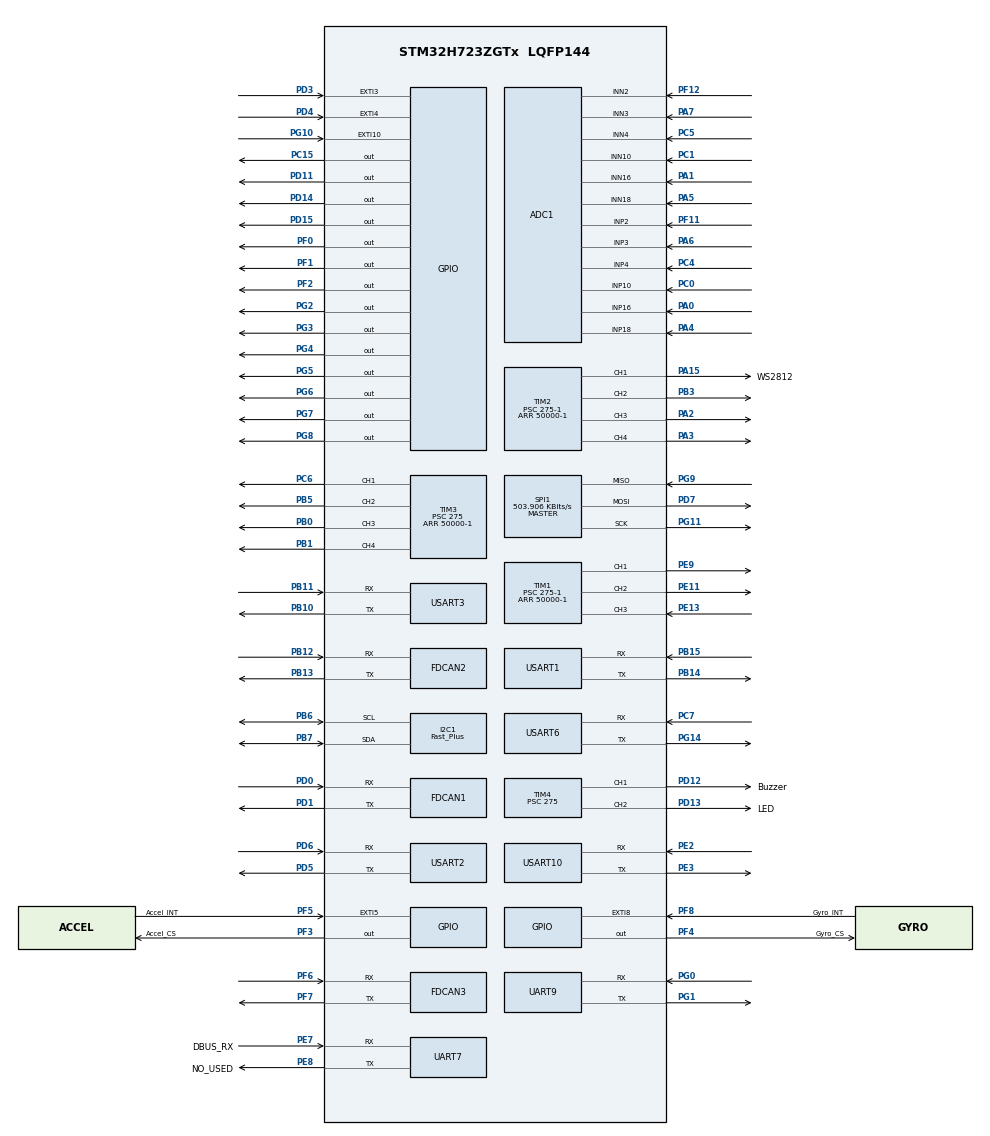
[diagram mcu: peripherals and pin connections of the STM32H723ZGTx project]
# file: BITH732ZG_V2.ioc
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ADC1.Channel-0\#ChannelRegularConversion=ADC_CHANNEL_16
ADC1.NbrOfConversionFlag=1
ADC1.OffsetNumber-0\#ChannelRegularConversion=ADC_OFFSET_NONE
ADC1.OffsetSignedSaturation-0\#ChannelRegularConversion=DISABLE
ADC1.Rank-0\#ChannelRegularConversion=1
ADC1.SamplingTime-0\#ChannelRegularConversion=ADC_SAMPLETIME_1CYCLE_5
ADC1.SingleDiff-0\#ChannelRegularConversion=ADC_DIFFERENTIAL_ENDED
ADC1.master=1
CORTEX_M7.CPU_DCache=Enabled
CORTEX_M7.CPU_ICache=Enabled
CORTEX_M7.MPU_Control=__NULL
CORTEX_M7.default_mode_Activation=1
Dma.Request0=UART7_RX
Dma.Request1=UART9_RX
Dma.Request10=USART10_TX
Dma.Request2=UART9_TX
Dma.Request3=USART2_RX
Dma.Request4=USART2_TX
Dma.Request5=USART3_RX
Dma.Request6=USART3_TX
Dma.Request7=USART6_RX
Dma.Request8=USART6_TX
Dma.Request9=USART10_RX
Dma.UART7_RX.0.Direction=DMA_PERIPH_TO_MEMORY
Dma.UART7_RX.0.EventEnable=DISABLE
Dma.UART7_RX.0.FIFOMode=DMA_FIFOMODE_DISABLE
Dma.UART7_RX.0.Instance=DMA1_Stream0
Dma.UART7_RX.0.MemDataAlignment=DMA_MDATAALIGN_BYTE
Dma.UART7_RX.0.MemInc=DMA_MINC_ENABLE
Dma.UART7_RX.0.Mode=DMA_CIRCULAR
Dma.UART7_RX.0.PeriphDataAlignment=DMA_PDATAALIGN_BYTE
Dma.UART7_RX.0.PeriphInc=DMA_PINC_DISABLE
Dma.UART7_RX.0.Polarity=HAL_DMAMUX_REQ_GEN_RISING
Dma.UART7_RX.0.Priority=DMA_PRIORITY_VERY_HIGH
Dma.UART7_RX.0.RequestNumber=1
Dma.UART7_RX.0.SignalID=NONE
Dma.UART7_RX.0.SyncEnable=DISABLE
Dma.UART7_RX.0.SyncPolarity=HAL_DMAMUX_SYNC_NO_EVENT
Dma.UART7_RX.0.SyncRequestNumber=1
Dma.UART7_RX.0.SyncSignalID=NONE
Dma.UART9_RX.1.Direction=DMA_PERIPH_TO_MEMORY
Dma.UART9_RX.1.EventEnable=DISABLE
Dma.UART9_RX.1.FIFOMode=DMA_FIFOMODE_DISABLE
Dma.UART9_RX.1.Instance=DMA1_Stream1
Dma.UART9_RX.1.MemDataAlignment=DMA_MDATAALIGN_BYTE
Dma.UART9_RX.1.MemInc=DMA_MINC_ENABLE
Dma.UART9_RX.1.Mode=DMA_NORMAL
Dma.UART9_RX.1.PeriphDataAlignment=DMA_PDATAALIGN_BYTE
Dma.UART9_RX.1.PeriphInc=DMA_PINC_DISABLE
Dma.UART9_RX.1.Polarity=HAL_DMAMUX_REQ_GEN_RISING
Dma.UART9_RX.1.Priority=DMA_PRIORITY_LOW
Dma.UART9_RX.1.RequestNumber=1
Dma.UART9_RX.1.SignalID=NONE
Dma.UART9_RX.1.SyncEnable=DISABLE
Dma.UART9_RX.1.SyncPolarity=HAL_DMAMUX_SYNC_NO_EVENT
Dma.UART9_RX.1.SyncRequestNumber=1
Dma.UART9_RX.1.SyncSignalID=NONE
Dma.UART9_TX.2.Direction=DMA_MEMORY_TO_PERIPH
Dma.UART9_TX.2.EventEnable=DISABLE
Dma.UART9_TX.2.FIFOMode=DMA_FIFOMODE_DISABLE
Dma.UART9_TX.2.Instance=DMA1_Stream2
Dma.UART9_TX.2.MemDataAlignment=DMA_MDATAALIGN_BYTE
Dma.UART9_TX.2.MemInc=DMA_MINC_ENABLE
Dma.UART9_TX.2.Mode=DMA_NORMAL
Dma.UART9_TX.2.PeriphDataAlignment=DMA_PDATAALIGN_BYTE
Dma.UART9_TX.2.PeriphInc=DMA_PINC_DISABLE
Dma.UART9_TX.2.Polarity=HAL_DMAMUX_REQ_GEN_RISING
Dma.UART9_TX.2.Priority=DMA_PRIORITY_LOW
Dma.UART9_TX.2.RequestNumber=1
Dma.UART9_TX.2.SignalID=NONE
Dma.UART9_TX.2.SyncEnable=DISABLE
Dma.UART9_TX.2.SyncPolarity=HAL_DMAMUX_SYNC_NO_EVENT
Dma.UART9_TX.2.SyncRequestNumber=1
Dma.UART9_TX.2.SyncSignalID=NONE
Dma.USART10_RX.9.Direction=DMA_PERIPH_TO_MEMORY
Dma.USART10_RX.9.EventEnable=DISABLE
Dma.USART10_RX.9.FIFOMode=DMA_FIFOMODE_DISABLE
Dma.USART10_RX.9.Instance=DMA2_Stream3
Dma.USART10_RX.9.MemDataAlignment=DMA_MDATAALIGN_BYTE
Dma.USART10_RX.9.MemInc=DMA_MINC_ENABLE
Dma.USART10_RX.9.Mode=DMA_NORMAL
Dma.USART10_RX.9.PeriphDataAlignment=DMA_PDATAALIGN_BYTE
Dma.USART10_RX.9.PeriphInc=DMA_PINC_DISABLE
Dma.USART10_RX.9.Polarity=HAL_DMAMUX_REQ_GEN_RISING
Dma.USART10_RX.9.Priority=DMA_PRIORITY_LOW
Dma.USART10_RX.9.RequestNumber=1
Dma.USART10_RX.9.SignalID=NONE
Dma.USART10_RX.9.SyncEnable=DISABLE
Dma.USART10_RX.9.SyncPolarity=HAL_DMAMUX_SYNC_NO_EVENT
Dma.USART10_RX.9.SyncRequestNumber=1
Dma.USART10_RX.9.SyncSignalID=NONE
Dma.USART10_TX.10.Direction=DMA_MEMORY_TO_PERIPH
Dma.USART10_TX.10.EventEnable=DISABLE
Dma.USART10_TX.10.FIFOMode=DMA_FIFOMODE_DISABLE
Dma.USART10_TX.10.Instance=DMA2_Stream4
Dma.USART10_TX.10.MemDataAlignment=DMA_MDATAALIGN_BYTE
Dma.USART10_TX.10.MemInc=DMA_MINC_ENABLE
Dma.USART10_TX.10.Mode=DMA_NORMAL
Dma.USART10_TX.10.PeriphDataAlignment=DMA_PDATAALIGN_BYTE
Dma.USART10_TX.10.PeriphInc=DMA_PINC_DISABLE
Dma.USART10_TX.10.Polarity=HAL_DMAMUX_REQ_GEN_RISING
Dma.USART10_TX.10.Priority=DMA_PRIORITY_LOW
Dma.USART10_TX.10.RequestNumber=1
Dma.USART10_TX.10.SignalID=NONE
Dma.USART10_TX.10.SyncEnable=DISABLE
Dma.USART10_TX.10.SyncPolarity=HAL_DMAMUX_SYNC_NO_EVENT
Dma.USART10_TX.10.SyncRequestNumber=1
Dma.USART10_TX.10.SyncSignalID=NONE
Dma.USART2_RX.3.Direction=DMA_PERIPH_TO_MEMORY
Dma.USART2_RX.3.EventEnable=DISABLE
Dma.USART2_RX.3.FIFOMode=DMA_FIFOMODE_DISABLE
Dma.USART2_RX.3.Instance=DMA1_Stream5
Dma.USART2_RX.3.MemDataAlignment=DMA_MDATAALIGN_BYTE
Dma.USART2_RX.3.MemInc=DMA_MINC_ENABLE
Dma.USART2_RX.3.Mode=DMA_NORMAL
Dma.USART2_RX.3.PeriphDataAlignment=DMA_PDATAALIGN_BYTE
Dma.USART2_RX.3.PeriphInc=DMA_PINC_DISABLE
Dma.USART2_RX.3.Polarity=HAL_DMAMUX_REQ_GEN_RISING
Dma.USART2_RX.3.Priority=DMA_PRIORITY_LOW
Dma.USART2_RX.3.RequestNumber=1
Dma.USART2_RX.3.SignalID=NONE
Dma.USART2_RX.3.SyncEnable=DISABLE
Dma.USART2_RX.3.SyncPolarity=HAL_DMAMUX_SYNC_NO_EVENT
Dma.USART2_RX.3.SyncRequestNumber=1
Dma.USART2_RX.3.SyncSignalID=NONE
Dma.USART2_TX.4.Direction=DMA_MEMORY_TO_PERIPH
Dma.USART2_TX.4.EventEnable=DISABLE
Dma.USART2_TX.4.FIFOMode=DMA_FIFOMODE_DISABLE
Dma.USART2_TX.4.Instance=DMA1_Stream6
Dma.USART2_TX.4.MemDataAlignment=DMA_MDATAALIGN_BYTE
Dma.USART2_TX.4.MemInc=DMA_MINC_ENABLE
Dma.USART2_TX.4.Mode=DMA_NORMAL
Dma.USART2_TX.4.PeriphDataAlignment=DMA_PDATAALIGN_BYTE
Dma.USART2_TX.4.PeriphInc=DMA_PINC_DISABLE
Dma.USART2_TX.4.Polarity=HAL_DMAMUX_REQ_GEN_RISING
Dma.USART2_TX.4.Priority=DMA_PRIORITY_LOW
Dma.USART2_TX.4.RequestNumber=1
Dma.USART2_TX.4.SignalID=NONE
Dma.USART2_TX.4.SyncEnable=DISABLE
Dma.USART2_TX.4.SyncPolarity=HAL_DMAMUX_SYNC_NO_EVENT
Dma.USART2_TX.4.SyncRequestNumber=1
Dma.USART2_TX.4.SyncSignalID=NONE
Dma.USART3_RX.5.Direction=DMA_PERIPH_TO_MEMORY
Dma.USART3_RX.5.EventEnable=DISABLE
Dma.USART3_RX.5.FIFOMode=DMA_FIFOMODE_DISABLE
Dma.USART3_RX.5.Instance=DMA1_Stream7
Dma.USART3_RX.5.MemDataAlignment=DMA_MDATAALIGN_BYTE
Dma.USART3_RX.5.MemInc=DMA_MINC_ENABLE
Dma.USART3_RX.5.Mode=DMA_NORMAL
Dma.USART3_RX.5.PeriphDataAlignment=DMA_PDATAALIGN_BYTE
Dma.USART3_RX.5.PeriphInc=DMA_PINC_DISABLE
Dma.USART3_RX.5.Polarity=HAL_DMAMUX_REQ_GEN_RISING
Dma.USART3_RX.5.Priority=DMA_PRIORITY_LOW
Dma.USART3_RX.5.RequestNumber=1
Dma.USART3_RX.5.SignalID=NONE
Dma.USART3_RX.5.SyncEnable=DISABLE
Dma.USART3_RX.5.SyncPolarity=HAL_DMAMUX_SYNC_NO_EVENT
Dma.USART3_RX.5.SyncRequestNumber=1
Dma.USART3_RX.5.SyncSignalID=NONE
Dma.USART3_TX.6.Direction=DMA_MEMORY_TO_PERIPH
Dma.USART3_TX.6.EventEnable=DISABLE
Dma.USART3_TX.6.FIFOMode=DMA_FIFOMODE_DISABLE
Dma.USART3_TX.6.Instance=DMA2_Stream0
Dma.USART3_TX.6.MemDataAlignment=DMA_MDATAALIGN_BYTE
Dma.USART3_TX.6.MemInc=DMA_MINC_ENABLE
Dma.USART3_TX.6.Mode=DMA_NORMAL
Dma.USART3_TX.6.PeriphDataAlignment=DMA_PDATAALIGN_BYTE
Dma.USART3_TX.6.PeriphInc=DMA_PINC_DISABLE
Dma.USART3_TX.6.Polarity=HAL_DMAMUX_REQ_GEN_RISING
Dma.USART3_TX.6.Priority=DMA_PRIORITY_LOW
Dma.USART3_TX.6.RequestNumber=1
Dma.USART3_TX.6.SignalID=NONE
Dma.USART3_TX.6.SyncEnable=DISABLE
Dma.USART3_TX.6.SyncPolarity=HAL_DMAMUX_SYNC_NO_EVENT
Dma.USART3_TX.6.SyncRequestNumber=1
Dma.USART3_TX.6.SyncSignalID=NONE
Dma.USART6_RX.7.Direction=DMA_PERIPH_TO_MEMORY
Dma.USART6_RX.7.EventEnable=DISABLE
Dma.USART6_RX.7.FIFOMode=DMA_FIFOMODE_DISABLE
Dma.USART6_RX.7.Instance=DMA2_Stream1
Dma.USART6_RX.7.MemDataAlignment=DMA_MDATAALIGN_BYTE
Dma.USART6_RX.7.MemInc=DMA_MINC_ENABLE
Dma.USART6_RX.7.Mode=DMA_NORMAL
Dma.USART6_RX.7.PeriphDataAlignment=DMA_PDATAALIGN_BYTE
Dma.USART6_RX.7.PeriphInc=DMA_PINC_DISABLE
Dma.USART6_RX.7.Polarity=HAL_DMAMUX_REQ_GEN_RISING
Dma.USART6_RX.7.Priority=DMA_PRIORITY_LOW
Dma.USART6_RX.7.RequestNumber=1
Dma.USART6_RX.7.SignalID=NONE
Dma.USART6_RX.7.SyncEnable=DISABLE
Dma.USART6_RX.7.SyncPolarity=HAL_DMAMUX_SYNC_NO_EVENT
Dma.USART6_RX.7.SyncRequestNumber=1
Dma.USART6_RX.7.SyncSignalID=NONE
Dma.USART6_TX.8.Direction=DMA_MEMORY_TO_PERIPH
Dma.USART6_TX.8.EventEnable=DISABLE
Dma.USART6_TX.8.FIFOMode=DMA_FIFOMODE_DISABLE
Dma.USART6_TX.8.Instance=DMA2_Stream2
Dma.USART6_TX.8.MemDataAlignment=DMA_MDATAALIGN_BYTE
Dma.USART6_TX.8.MemInc=DMA_MINC_ENABLE
Dma.USART6_TX.8.Mode=DMA_NORMAL
Dma.USART6_TX.8.PeriphDataAlignment=DMA_PDATAALIGN_BYTE
Dma.USART6_TX.8.PeriphInc=DMA_PINC_DISABLE
Dma.USART6_TX.8.Polarity=HAL_DMAMUX_REQ_GEN_RISING
Dma.USART6_TX.8.Priority=DMA_PRIORITY_LOW
Dma.USART6_TX.8.RequestNumber=1
Dma.USART6_TX.8.SignalID=NONE
Dma.USART6_TX.8.SyncEnable=DISABLE
Dma.USART6_TX.8.SyncPolarity=HAL_DMAMUX_SYNC_NO_EVENT
Dma.USART6_TX.8.SyncRequestNumber=1
Dma.USART6_TX.8.SyncSignalID=NONE
FDCAN1.CalculateBaudRateNominal=1000000
FDCAN1.CalculateTimeBitNominal=1000
FDCAN1.CalculateTimeQuantumNominal=83.33333333333333
FDCAN1.DataPrescaler=2
FDCAN1.DataTimeSeg1=10
FDCAN1.DataTimeSeg2=6
FDCAN1.NominalPrescaler=1
FDCAN1.NominalTimeSeg1=9
FDCAN1.NominalTimeSeg2=2
FDCAN1.RxBufferSize=FDCAN_DATA_BYTES_64
FDCAN1.RxFifo0ElmtSize=FDCAN_DATA_BYTES_64
FDCAN1.RxFifo0ElmtsNbr=32
FDCAN1.RxFifo1ElmtSize=FDCAN_DATA_BYTES_64
FDCAN1.RxFifo1ElmtsNbr=32
FDCAN1.StdFiltersNbr=8
FDCAN1.TransmitPause=DISABLE
FDCAN1.TxBuffersNbr=16
FDCAN1.TxElmtSize=FDCAN_DATA_BYTES_64
FDCAN1.TxEventsNbr=0
FDCAN1.TxFifoQueueElmtsNbr=16
FDCAN2.CalculateBaudRateNominal=1000000
FDCAN2.CalculateTimeBitNominal=1000
FDCAN2.CalculateTimeQuantumNominal=83.33333333333333
FDCAN2.DataPrescaler=2
FDCAN2.DataTimeSeg1=10
FDCAN2.DataTimeSeg2=6
FDCAN2.NominalPrescaler=1
FDCAN2.NominalTimeSeg1=9
FDCAN2.NominalTimeSeg2=2
FDCAN2.RxBufferSize=FDCAN_DATA_BYTES_64
FDCAN2.RxFifo0ElmtSize=FDCAN_DATA_BYTES_64
FDCAN2.RxFifo0ElmtsNbr=32
FDCAN2.RxFifo1ElmtSize=FDCAN_DATA_BYTES_64
FDCAN2.StdFiltersNbr=8
FDCAN2.TxBuffersNbr=16
FDCAN2.TxElmtSize=FDCAN_DATA_BYTES_64
FDCAN2.TxEventsNbr=0
FDCAN2.TxFifoQueueElmtsNbr=16
FDCAN3.CalculateBaudRateNominal=1000000
FDCAN3.CalculateTimeBitNominal=1000
FDCAN3.CalculateTimeQuantumNominal=83.33333333333333
FDCAN3.DataPrescaler=2
FDCAN3.DataSyncJumpWidth=1
FDCAN3.DataTimeSeg1=10
FDCAN3.DataTimeSeg2=6
FDCAN3.NominalPrescaler=1
FDCAN3.NominalTimeSeg1=9
FDCAN3.NominalTimeSeg2=2
FDCAN3.RxBufferSize=FDCAN_DATA_BYTES_64
FDCAN3.RxFifo0ElmtSize=FDCAN_DATA_BYTES_64
FDCAN3.RxFifo0ElmtsNbr=32
FDCAN3.RxFifo1ElmtSize=FDCAN_DATA_BYTES_64
FDCAN3.RxFifo1ElmtsNbr=32
FDCAN3.StdFiltersNbr=8
FDCAN3.TxBuffersNbr=16
FDCAN3.TxElmtSize=FDCAN_DATA_BYTES_64
FDCAN3.TxEventsNbr=0
FDCAN3.TxFifoQueueElmtsNbr=16
FREERTOS.Tasks01=defaultTask,0,128,StartDefaultTask,Default,NULL,Dynamic,NULL,NULL
I2C1.I2C_Speed_Mode=I2C_Fast_Plus
I2C1.Timing=0x00601955
Mcu.Family=STM32H7
Mcu.Name=STM32H723ZGTx
Mcu.Package=LQFP144
NVIC.DMA1_Stream0_IRQn=true\:5\:0\:false\:false\:true\:true\:false\:true\:true
NVIC.DMA1_Stream1_IRQn=true\:5\:0\:false\:false\:true\:true\:false\:true\:true
NVIC.DMA1_Stream2_IRQn=true\:5\:0\:false\:false\:true\:true\:false\:true\:true
NVIC.DMA1_Stream5_IRQn=true\:5\:0\:false\:false\:true\:true\:false\:true\:true
NVIC.DMA1_Stream6_IRQn=true\:5\:0\:false\:false\:true\:true\:false\:true\:true
NVIC.DMA1_Stream7_IRQn=true\:5\:0\:false\:false\:true\:true\:false\:true\:true
NVIC.DMA2_Stream0_IRQn=true\:5\:0\:false\:false\:true\:true\:false\:true\:true
NVIC.DMA2_Stream1_IRQn=true\:5\:0\:false\:false\:true\:true\:false\:true\:true
NVIC.DMA2_Stream2_IRQn=true\:5\:0\:false\:false\:true\:true\:false\:true\:true
NVIC.DMA2_Stream3_IRQn=true\:5\:0\:false\:false\:true\:true\:false\:true\:true
NVIC.DMA2_Stream4_IRQn=true\:5\:0\:false\:false\:true\:true\:false\:true\:true
NVIC.EXTI9_5_IRQn=true\:5\:0\:false\:false\:true\:true\:true\:true\:true
NVIC.FDCAN1_IT0_IRQn=true\:5\:0\:false\:false\:true\:true\:true\:true\:true
NVIC.FDCAN2_IT0_IRQn=true\:5\:0\:false\:false\:true\:true\:true\:true\:true
NVIC.FDCAN3_IT0_IRQn=true\:5\:0\:false\:false\:true\:true\:true\:true\:true
NVIC.PriorityGroup=NVIC_PRIORITYGROUP_4
NVIC.SPI1_IRQn=true\:5\:0\:false\:false\:true\:true\:true\:true\:true
NVIC.TIM24_IRQn=true\:5\:0\:false\:false\:false\:true\:true\:true\:true
NVIC.UART7_IRQn=true\:5\:0\:false\:false\:true\:true\:true\:true\:true
NVIC.UART9_IRQn=true\:5\:0\:false\:false\:true\:true\:true\:true\:true
NVIC.USART10_IRQn=true\:5\:0\:false\:false\:true\:true\:true\:true\:true
NVIC.USART1_IRQn=true\:5\:0\:false\:false\:true\:true\:true\:true\:true
NVIC.USART2_IRQn=true\:5\:0\:false\:false\:true\:true\:true\:true\:true
NVIC.USART3_IRQn=true\:5\:0\:false\:false\:true\:true\:true\:true\:true
NVIC.USART6_IRQn=true\:5\:0\:false\:false\:true\:true\:true\:true\:true
PA0.Mode=IN16-Differential
PA0.Signal=ADC1_INP16
PA1.Mode=IN16-Differential
PA1.Signal=ADC1_INN16
PA13(JTMS/SWDIO).Mode=Serial_Wire
PA13(JTMS/SWDIO).Signal=DEBUG_JTMS-SWDIO
PA14(JTCK/SWCLK).Mode=Serial_Wire
PA14(JTCK/SWCLK).Signal=DEBUG_JTCK-SWCLK
PA15(JTDI).GPIO_Label=WS2812
PA15(JTDI).Signal=S_TIM2_CH1_ETR
PA2.Signal=S_TIM2_CH3
PA3.Signal=S_TIM2_CH4
PA4.Signal=ADCx_INP18
PA5.Signal=ADCx_INN18
PA6.Signal=ADCx_INP3
PA7.Signal=ADCx_INN3
PB0.Signal=S_TIM3_CH3
PB1.Signal=S_TIM3_CH4
PB10.GPIO_Speed=GPIO_SPEED_FREQ_VERY_HIGH
PB10.Mode=Asynchronous
PB10.Signal=USART3_TX
PB11.GPIO_Speed=GPIO_SPEED_FREQ_VERY_HIGH
PB11.Mode=Asynchronous
PB11.Signal=USART3_RX
PB12.GPIO_Speed=GPIO_SPEED_FREQ_VERY_HIGH
PB12.Mode=FDCAN_Activate
PB12.Signal=FDCAN2_RX
PB13.GPIO_Speed=GPIO_SPEED_FREQ_VERY_HIGH
PB13.Mode=FDCAN_Activate
PB13.Signal=FDCAN2_TX
PB14.GPIO_Speed=GPIO_SPEED_FREQ_VERY_HIGH
PB14.Mode=Asynchronous
PB14.Signal=USART1_TX
PB15.GPIO_Speed=GPIO_SPEED_FREQ_VERY_HIGH
PB15.Mode=Asynchronous
PB15.Signal=USART1_RX
PB3(JTDO/TRACESWO).Signal=S_TIM2_CH2
PB5.Signal=S_TIM3_CH2
PB6.Mode=I2C
PB6.Signal=I2C1_SCL
PB7.Mode=I2C
PB7.Signal=I2C1_SDA
PC0.Signal=ADCx_INP10
PC1.Signal=ADCx_INN10
PC10.Signal=SDMMC1_D2
PC11.Signal=SDMMC1_D3
PC12.Signal=SDMMC1_CK
PC15-OSC32_OUT.GPIO_PuPd=GPIO_PULLDOWN
PC15-OSC32_OUT.PinState=GPIO_PIN_SET
PC15-OSC32_OUT.Signal=GPIO_Output
PC4.Signal=ADCx_INP4
PC5.Signal=ADCx_INN4
PC6.Signal=S_TIM3_CH1
PC7.GPIO_Speed=GPIO_SPEED_FREQ_VERY_HIGH
PC7.Mode=Asynchronous
PC7.Signal=USART6_RX
PC8.Signal=SDMMC1_D0
PC9.Signal=SDMMC1_D1
PD0.GPIO_Speed=GPIO_SPEED_FREQ_VERY_HIGH
PD0.Mode=FDCAN_Activate
PD0.Signal=FDCAN1_RX
PD1.GPIO_Speed=GPIO_SPEED_FREQ_VERY_HIGH
PD1.Mode=FDCAN_Activate
PD1.Signal=FDCAN1_TX
PD11.Signal=GPIO_Output
PD12.GPIO_Label=Buzzer
PD12.Signal=S_TIM4_CH1
PD13.GPIO_Label=LED
PD13.Signal=S_TIM4_CH2
PD14.Signal=GPIO_Output
PD15.Signal=GPIO_Output
PD2.Signal=SDMMC1_CMD
PD3.Signal=GPXTI3
PD4.Signal=GPXTI4
PD5.GPIO_Speed=GPIO_SPEED_FREQ_VERY_HIGH
PD5.Mode=Asynchronous
PD5.Signal=USART2_TX
PD6.GPIO_Speed=GPIO_SPEED_FREQ_VERY_HIGH
PD6.Mode=Asynchronous
PD6.Signal=USART2_RX
PD7.GPIO_Speed=GPIO_SPEED_FREQ_VERY_HIGH
PD7.Mode=Full_Duplex_Master
PD7.Signal=SPI1_MOSI
PE11.Signal=S_TIM1_CH2
PE13.Signal=S_TIM1_CH3
PE14.Signal=S_TIM1_CH4
PE2.GPIO_Speed=GPIO_SPEED_FREQ_VERY_HIGH
PE2.Mode=Asynchronous
PE2.Signal=USART10_RX
PE3.GPIO_Speed=GPIO_SPEED_FREQ_VERY_HIGH
PE3.Mode=Asynchronous
PE3.Signal=USART10_TX
PE7.GPIO_Label=DBUS_RX
PE7.GPIO_Speed=GPIO_SPEED_FREQ_VERY_HIGH
PE7.Mode=Asynchronous
PE7.Signal=UART7_RX
PE8.GPIO_Label=NO_USED
PE8.GPIO_Speed=GPIO_SPEED_FREQ_VERY_HIGH
PE8.Mode=Asynchronous
PE8.Signal=UART7_TX
PE9.Signal=S_TIM1_CH1
PF0.GPIO_PuPd=GPIO_PULLDOWN
PF0.PinState=GPIO_PIN_SET
PF0.Signal=GPIO_Output
PF1.GPIO_PuPd=GPIO_PULLDOWN
PF1.PinState=GPIO_PIN_SET
PF1.Signal=GPIO_Output
PF11.Mode=IN2-Differential
PF11.Signal=ADC1_INP2
PF12.Mode=IN2-Differential
PF12.Signal=ADC1_INN2
PF2.GPIO_PuPd=GPIO_PULLDOWN
PF2.PinState=GPIO_PIN_SET
PF2.Signal=GPIO_Output
PF3.GPIO_Label=Accel_CS
PF3.GPIO_PuPd=GPIO_PULLUP
PF3.GPIO_Speed=GPIO_SPEED_FREQ_VERY_HIGH
PF3.PinState=GPIO_PIN_SET
PF3.Signal=GPIO_Output
PF4.GPIO_Label=Gyro_CS
PF4.GPIO_PuPd=GPIO_PULLUP
PF4.GPIO_Speed=GPIO_SPEED_FREQ_VERY_HIGH
PF4.PinState=GPIO_PIN_SET
PF4.Signal=GPIO_Output
PF5.GPIO_Label=Accel_INT
PF5.GPIO_ModeDefaultEXTI=GPIO_MODE_IT_FALLING
PF5.GPIO_PuPd=GPIO_PULLUP
PF5.Signal=GPXTI5
PF6.GPIO_Speed=GPIO_SPEED_FREQ_VERY_HIGH
PF6.Mode=FDCAN_Activate
PF6.Signal=FDCAN3_RX
PF7.GPIO_Speed=GPIO_SPEED_FREQ_VERY_HIGH
PF7.Mode=FDCAN_Activate
PF7.Signal=FDCAN3_TX
PF8.GPIO_Label=Gyro_INT
PF8.GPIO_ModeDefaultEXTI=GPIO_MODE_IT_FALLING
PF8.GPIO_PuPd=GPIO_PULLUP
PF8.Signal=GPXTI8
PG0.GPIO_Speed=GPIO_SPEED_FREQ_VERY_HIGH
PG0.Mode=Asynchronous
PG0.Signal=UART9_RX
PG1.GPIO_Speed=GPIO_SPEED_FREQ_VERY_HIGH
PG1.Mode=Asynchronous
PG1.Signal=UART9_TX
PG10.Signal=GPXTI10
PG11.GPIO_Speed=GPIO_SPEED_FREQ_VERY_HIGH
PG11.Mode=Full_Duplex_Master
PG11.Signal=SPI1_SCK
PG14.GPIO_Speed=GPIO_SPEED_FREQ_VERY_HIGH
PG14.Mode=Asynchronous
PG14.Signal=USART6_TX
PG2.Signal=GPIO_Output
PG3.Signal=GPIO_Output
PG4.Signal=GPIO_Output
PG5.Signal=GPIO_Output
PG6.Signal=GPIO_Output
PG7.Signal=GPIO_Output
PG8.Signal=GPIO_Output
PG9.GPIO_Speed=GPIO_SPEED_FREQ_VERY_HIGH
PG9.Mode=Full_Duplex_Master
PG9.Signal=SPI1_MISO
PH0-OSC_IN.Mode=HSE-External-Oscillator
PH0-OSC_IN.Signal=RCC_OSC_IN
PH1-OSC_OUT.Mode=HSE-External-Oscillator
PH1-OSC_OUT.Signal=RCC_OSC_OUT
ProjectManager.HeapSize=0x1000
ProjectManager.StackSize=0x1000
ProjectManager.TargetToolchain=CMake
RCC.ADCFreq_Value=96000000
RCC.APB1Freq_Value=137500000
RCC.APB2Freq_Value=137500000
RCC.APB3Freq_Value=137500000
RCC.APB4Freq_Value=137500000
RCC.CortexFreq_Value=550000000
RCC.D1PPRE=RCC_APB3_DIV2
RCC.D2PPRE1=RCC_APB1_DIV2
RCC.D2PPRE2=RCC_APB2_DIV2
RCC.D3PPRE=RCC_APB4_DIV2
RCC.DIVM1=4
RCC.DIVM2=4
RCC.DIVN1=34
RCC.DIVN2=12
RCC.DIVP1=1
RCC.DIVQ1=3
RCC.DIVR2=1
RCC.FDCANCLockSelection=RCC_FDCANCLKSOURCE_HSE
RCC.HCLKFreq_Value=275000000
RCC.HPRE=RCC_HCLK_DIV2
RCC.HSE_VALUE=12000000
RCC.I2C123CLockSelection=RCC_I2C1235CLKSOURCE_PLL3
RCC.PLL1_VCI_Range=RCC_PLL1VCIRANGE_3
RCC.PLL1_VCO_SEL-AdvancedSettings=RCC_PLL1VCOMEDIUM
RCC.PLL2FRACN=0
RCC.PLL2_VCI_Range=RCC_PLL2VCIRANGE_3
RCC.PLL2_VCO_SEL-AdvancedSettings=RCC_PLL2VCOWIDE
RCC.PLL3FRACN=0
RCC.PLL3_VCO_SEL-AdvancedSettings=RCC_PLL3VCOWIDE
RCC.PLLFRACN=3072
RCC.PREFETCH_ENABLE=1
RCC.SDMMC1CLockSelection=RCC_SDMMCCLKSOURCE_PLL2
RCC.SPI123CLockSelection=RCC_SPI123CLKSOURCE_PLL3
RCC.SYSCLKFreq_VALUE=550000000
RCC.SYSCLKSource=RCC_SYSCLKSOURCE_PLLCLK
RCC.USART16CLockSelection=RCC_USART16910CLKSOURCE_PLL3
RCC.USART234578CLockSelection=RCC_USART234578CLKSOURCE_PLL3
RCC.USBFreq_Value=183333333.33333334
SH.ADCx_INN10.0=ADC1_INN10,IN10-Differential
SH.ADCx_INN18.0=ADC1_INN18,IN18-Differential
SH.ADCx_INN3.0=ADC1_INN3,IN3-Differential
SH.ADCx_INN4.0=ADC1_INN4,IN4-Differential
SH.ADCx_INP10.0=ADC1_INP10,IN10-Differential
SH.ADCx_INP18.0=ADC1_INP18,IN18-Differential
SH.ADCx_INP3.0=ADC1_INP3,IN3-Differential
SH.ADCx_INP4.0=ADC1_INP4,IN4-Differential
SH.S_TIM1_CH1.0=TIM1_CH1,PWM Generation1 CH1
SH.S_TIM1_CH2.0=TIM1_CH2,PWM Generation2 CH2
SH.S_TIM1_CH3.0=TIM1_CH3,Input_Capture3_from_TI3
SH.S_TIM1_CH4.0=TIM1_CH4
SH.S_TIM2_CH1_ETR.0=TIM2_CH1,PWM Generation1 CH1
SH.S_TIM2_CH2.0=TIM2_CH2,PWM Generation2 CH2
SH.S_TIM2_CH3.0=TIM2_CH3,PWM Generation3 CH3
SH.S_TIM2_CH4.0=TIM2_CH4,PWM Generation4 CH4
SH.S_TIM3_CH1.0=TIM3_CH1,PWM Generation1 CH1
SH.S_TIM3_CH2.0=TIM3_CH2,PWM Generation2 CH2
SH.S_TIM3_CH3.0=TIM3_CH3,PWM Generation3 CH3
SH.S_TIM3_CH4.0=TIM3_CH4,PWM Generation4 CH4
SH.S_TIM4_CH1.0=TIM4_CH1,PWM Generation1 CH1
SH.S_TIM4_CH2.0=TIM4_CH2,PWM Generation2 CH2
SPI1.BaudRatePrescaler=SPI_BAUDRATEPRESCALER_256
SPI1.CLKPhase=SPI_PHASE_2EDGE
SPI1.CLKPolarity=SPI_POLARITY_HIGH
SPI1.CalculateBaudRate=503.906 KBits/s
SPI1.DataSize=SPI_DATASIZE_8BIT
SPI1.Direction=SPI_DIRECTION_2LINES
SPI1.Mode=SPI_MODE_MASTER
SPI1.VirtualType=VM_MASTER
STMicroelectronics.X-CUBE-AZRTOS-H7.3.2.0_IsAnAzureRtosMw=true
TIM1.Channel-Input_Capture3_from_TI3=TIM_CHANNEL_3
TIM1.Channel-Input_Capture4_from_TI3_63=TIM_CHANNEL_4
TIM1.Channel-PWM\ Generation1\ CH1=TIM_CHANNEL_1
TIM1.Channel-PWM\ Generation2\ CH2=TIM_CHANNEL_2
TIM1.Period=50000-1
TIM1.Prescaler=275-1
TIM2.Channel-PWM\ Generation1\ CH1=TIM_CHANNEL_1
TIM2.Channel-PWM\ Generation2\ CH2=TIM_CHANNEL_2
TIM2.Channel-PWM\ Generation3\ CH3=TIM_CHANNEL_3
TIM2.Channel-PWM\ Generation4\ CH4=TIM_CHANNEL_4
TIM2.Period=50000-1
TIM2.Prescaler=275-1
TIM24.AutoReloadPreload=TIM_AUTORELOAD_PRELOAD_ENABLE
TIM24.Channel-Output\ Compare1\ No\ Output=TIM_CHANNEL_1
TIM24.Channel-Output\ Compare2\ No\ Output=TIM_CHANNEL_2
TIM24.Channel-Output\ Compare3\ No\ Output=TIM_CHANNEL_3
TIM24.Channel-Output\ Compare4\ No\ Output=TIM_CHANNEL_4
TIM24.Period=4294967295
TIM24.Prescaler=275-1
TIM3.Channel-PWM\ Generation1\ CH1=TIM_CHANNEL_1
TIM3.Channel-PWM\ Generation2\ CH2=TIM_CHANNEL_2
TIM3.Channel-PWM\ Generation3\ CH3=TIM_CHANNEL_3
TIM3.Channel-PWM\ Generation4\ CH4=TIM_CHANNEL_4
TIM3.Period=50000-1
TIM3.Prescaler=275
TIM4.Channel-PWM\ Generation1\ CH1=TIM_CHANNEL_1
TIM4.Channel-PWM\ Generation2\ CH2=TIM_CHANNEL_2
TIM4.Period=50000-1
TIM4.Prescaler=275
USART1.VirtualMode-Asynchronous=VM_ASYNC
USART10.VirtualMode-Asynchronous=VM_ASYNC
USART2.VirtualMode-Asynchronous=VM_ASYNC
USART3.VirtualMode-Asynchronous=VM_ASYNC
USART6.VirtualMode-Asynchronous=VM_ASYNC
VP_FREERTOS_VS_CMSIS_V1.Mode=CMSIS_V1
VP_MEMORYMAP_VS_MEMORYMAP.Mode=CurAppReg
VP_TIM1_VS_ClockSourceINT.Mode=Internal
VP_TIM1_VS_indirect_ch3.Mode=Input_Capture4_from_TI3_63
VP_TIM24_VS_ClockSourceINT.Mode=Internal
VP_TIM24_VS_no_output1.Mode=Output Compare1 No Output
VP_TIM24_VS_no_output2.Mode=Output Compare2 No Output
VP_TIM24_VS_no_output3.Mode=Output Compare3 No Output
VP_TIM24_VS_no_output4.Mode=Output Compare4 No Output
VP_TIM2_VS_ClockSourceINT.Mode=Internal
VP_TIM3_VS_ClockSourceINT.Mode=Internal
VP_TIM4_VS_ClockSourceINT.Mode=Internal
board=custom

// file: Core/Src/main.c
/* USER CODE BEGIN Header */
/**
  ******************************************************************************
  * @file           : main.c
  * @brief          : Main program body
  ******************************************************************************
  * @attention
  *
  * Copyright (c) 2024 STMicroelectronics.
  * All rights reserved.
  *
  * This software is licensed under terms that can be found in the LICENSE file
  * in the root directory of this software component.
  * If no LICENSE file comes with this software, it is provided AS-IS.
  *
  ******************************************************************************
  */
/* USER CODE END Header */
#include "main.h"
#include "cmsis_os.h"
#include "adc.h"
#include "dma.h"
#include "fdcan.h"
#include "i2c.h"
#include "memorymap.h"
#include "spi.h"
#include "tim.h"
#include "usart.h"
#include "gpio.h"

void SystemClock_Config(void);
void PeriphCommonClock_Config(void);
void MX_FREERTOS_Init(void);

int main(void)
{

  /* Enable the CPU Cache */

  /* Enable I-Cache---------------------------------------------------------*/
  SCB_EnableICache();

  /* Enable D-Cache---------------------------------------------------------*/
  SCB_EnableDCache();

  /* MCU Configuration--------------------------------------------------------*/

  /* Reset of all peripherals, Initializes the Flash interface and the Systick. */
  HAL_Init();

  /* Configure the system clock */
  SystemClock_Config();

  /* Configure the peripherals common clocks */
  PeriphCommonClock_Config();

  /* Initialize all configured peripherals */
  MX_GPIO_Init();
  MX_DMA_Init();
  MX_ADC1_Init();
  MX_FDCAN1_Init();
  MX_FDCAN2_Init();
  MX_FDCAN3_Init();
  MX_I2C1_Init();
  MX_SPI1_Init();
  MX_TIM1_Init();
  MX_TIM2_Init();
  MX_TIM3_Init();
  MX_TIM4_Init();
  MX_UART7_Init();
  MX_UART9_Init();
  MX_USART1_UART_Init();
  MX_USART2_UART_Init();
  MX_USART3_UART_Init();
  MX_USART6_UART_Init();
  MX_USART10_UART_Init();
  MX_TIM24_Init();

  /* Call init function for freertos objects (in cmsis_os2.c) */
  MX_FREERTOS_Init();

  /* Start scheduler */
  osKernelStart();

  /* We should never get here as control is now taken by the scheduler */

  /* Infinite loop */
  while (1)
  {

  }
}

void SystemClock_Config(void)
{
  RCC_OscInitTypeDef RCC_OscInitStruct = {0};
  RCC_ClkInitTypeDef RCC_ClkInitStruct = {0};

  /** Supply configuration update enable
  */
  HAL_PWREx_ConfigSupply(PWR_LDO_SUPPLY);

  /** Configure the main internal regulator output voltage
  */
  __HAL_PWR_VOLTAGESCALING_CONFIG(PWR_REGULATOR_VOLTAGE_SCALE0);

  while(!__HAL_PWR_GET_FLAG(PWR_FLAG_VOSRDY)) {}

  /** Initializes the RCC Oscillators according to the specified parameters
  * in the RCC_OscInitTypeDef structure.
  */
  RCC_OscInitStruct.OscillatorType = RCC_OSCILLATORTYPE_HSI|RCC_OSCILLATORTYPE_HSE;
  RCC_OscInitStruct.HSEState = RCC_HSE_ON;
  RCC_OscInitStruct.HSIState = RCC_HSI_DIV1;
  RCC_OscInitStruct.HSICalibrationValue = 64;
  RCC_OscInitStruct.PLL.PLLState = RCC_PLL_ON;
  RCC_OscInitStruct.PLL.PLLSource = RCC_PLLSOURCE_HSI;
  RCC_OscInitStruct.PLL.PLLM = 4;
  RCC_OscInitStruct.PLL.PLLN = 34;
  RCC_OscInitStruct.PLL.PLLP = 1;
  RCC_OscInitStruct.PLL.PLLQ = 3;
  RCC_OscInitStruct.PLL.PLLR = 2;
  RCC_OscInitStruct.PLL.PLLRGE = RCC_PLL1VCIRANGE_3;
  RCC_OscInitStruct.PLL.PLLVCOSEL = RCC_PLL1VCOWIDE;
  RCC_OscInitStruct.PLL.PLLFRACN = 3072;
  if (HAL_RCC_OscConfig(&RCC_OscInitStruct) != HAL_OK)
  {
    Error_Handler();
  }

  /** Initializes the CPU, AHB and APB buses clocks
  */
  RCC_ClkInitStruct.ClockType = RCC_CLOCKTYPE_HCLK|RCC_CLOCKTYPE_SYSCLK
                              |RCC_CLOCKTYPE_PCLK1|RCC_CLOCKTYPE_PCLK2
                              |RCC_CLOCKTYPE_D3PCLK1|RCC_CLOCKTYPE_D1PCLK1;
  RCC_ClkInitStruct.SYSCLKSource = RCC_SYSCLKSOURCE_PLLCLK;
  RCC_ClkInitStruct.SYSCLKDivider = RCC_SYSCLK_DIV1;
  RCC_ClkInitStruct.AHBCLKDivider = RCC_HCLK_DIV2;
  RCC_ClkInitStruct.APB3CLKDivider = RCC_APB3_DIV2;
  RCC_ClkInitStruct.APB1CLKDivider = RCC_APB1_DIV2;
  RCC_ClkInitStruct.APB2CLKDivider = RCC_APB2_DIV2;
  RCC_ClkInitStruct.APB4CLKDivider = RCC_APB4_DIV2;

  if (HAL_RCC_ClockConfig(&RCC_ClkInitStruct, FLASH_LATENCY_3) != HAL_OK)
  {
    Error_Handler();
  }
}

void PeriphCommonClock_Config(void)
{
  RCC_PeriphCLKInitTypeDef PeriphClkInitStruct = {0};

  /** Initializes the peripherals clock
  */
  PeriphClkInitStruct.PeriphClockSelection = RCC_PERIPHCLK_I2C1|RCC_PERIPHCLK_SPI1
                              |RCC_PERIPHCLK_USART1|RCC_PERIPHCLK_USART6
                              |RCC_PERIPHCLK_USART10|RCC_PERIPHCLK_UART9
                              |RCC_PERIPHCLK_UART7|RCC_PERIPHCLK_USART2
                              |RCC_PERIPHCLK_USART3;
  PeriphClkInitStruct.PLL3.PLL3M = 32;
  PeriphClkInitStruct.PLL3.PLL3N = 129;
  PeriphClkInitStruct.PLL3.PLL3P = 2;
  PeriphClkInitStruct.PLL3.PLL3Q = 2;
  PeriphClkInitStruct.PLL3.PLL3R = 2;
  PeriphClkInitStruct.PLL3.PLL3RGE = RCC_PLL3VCIRANGE_1;
  PeriphClkInitStruct.PLL3.PLL3VCOSEL = RCC_PLL3VCOWIDE;
  PeriphClkInitStruct.PLL3.PLL3FRACN = 0;
  PeriphClkInitStruct.Spi123ClockSelection = RCC_SPI123CLKSOURCE_PLL3;
  PeriphClkInitStruct.Usart234578ClockSelection = RCC_USART234578CLKSOURCE_PLL3;
  PeriphClkInitStruct.Usart16ClockSelection = RCC_USART16910CLKSOURCE_PLL3;
  PeriphClkInitStruct.I2c123ClockSelection = RCC_I2C1235CLKSOURCE_PLL3;
  if (HAL_RCCEx_PeriphCLKConfig(&PeriphClkInitStruct) != HAL_OK)
  {
    Error_Handler();
  }
}

void Error_Handler(void)
{
  __disable_irq();
  while (1)
  {
  }
}

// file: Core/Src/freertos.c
/* USER CODE BEGIN Header */
/**
  ******************************************************************************
  * File Name          : freertos.c
  * Description        : Code for freertos applications
  ******************************************************************************
  * @attention
  *
  * Copyright (c) 2024 STMicroelectronics.
  * All rights reserved.
  *
  * This software is licensed under terms that can be found in the LICENSE file
  * in the root directory of this software component.
  * If no LICENSE file comes with this software, it is provided AS-IS.
  *
  ******************************************************************************
  */
/* USER CODE END Header */

#include "FreeRTOS.h"
#include "task.h"
#include "main.h"
#include "cmsis_os.h"

/* USER CODE BEGIN Includes */
#include "task/test.h"
#include "task/ins.h"
#include "task/chassis.h"
#include "task/ui.h"
#include "task/com.h"
/* USER CODE END Includes */

osThreadId defaultTaskHandle;

void StartDefaultTask(void const * argument);

void MX_FREERTOS_Init(void); /* (MISRA C 2004 rule 8.1) */

/* GetIdleTaskMemory prototype (linked to static allocation support) */
void vApplicationGetIdleTaskMemory( StaticTask_t **ppxIdleTaskTCBBuffer, StackType_t **ppxIdleTaskStackBuffer, uint32_t *pulIdleTaskStackSize );

/* USER CODE BEGIN GET_IDLE_TASK_MEMORY */
static StaticTask_t xIdleTaskTCBBuffer;
static StackType_t xIdleStack[configMINIMAL_STACK_SIZE];

void vApplicationGetIdleTaskMemory( StaticTask_t **ppxIdleTaskTCBBuffer, StackType_t **ppxIdleTaskStackBuffer, uint32_t *pulIdleTaskStackSize )
{
  *ppxIdleTaskTCBBuffer = &xIdleTaskTCBBuffer;
  *ppxIdleTaskStackBuffer = &xIdleStack[0];
  *pulIdleTaskStackSize = configMINIMAL_STACK_SIZE;
  /* place for user code */
}
/* USER CODE END GET_IDLE_TASK_MEMORY */

void MX_FREERTOS_Init(void) {
  /* USER CODE BEGIN Init */
  LEDTaskStart();
  InsTaskStart();
  ChassisTaskStart();
  ComTaskStart();

  /* USER CODE END Init */

  /* Create the thread(s) */
  /* definition and creation of defaultTask */
  osThreadDef(defaultTask, StartDefaultTask, osPriorityNormal, 0, 128);
  defaultTaskHandle = osThreadCreate(osThread(defaultTask), NULL);

}

void StartDefaultTask(void const * argument)
{
  for(;;)
  {
    osDelay(1);
  }
}
